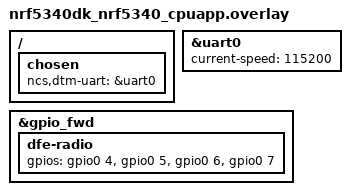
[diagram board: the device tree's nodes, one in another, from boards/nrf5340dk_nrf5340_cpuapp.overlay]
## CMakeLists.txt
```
#
# Copyright (c) 2023 Nordic Semiconductor ASA
#
# SPDX-License-Identifier: LicenseRef-Nordic-5-Clause
#

cmake_minimum_required(VERSION 3.20.0)

find_package(Zephyr REQUIRED HINTS $ENV{ZEPHYR_BASE})
project(remote_hci)

target_include_directories(app PRIVATE ./../rpc)
target_include_directories(app PRIVATE ./../src/transport)

# NORDIC SDK APP START
target_sources(app PRIVATE
  src/main.c
  ../src/transport/hci_uart.c
)
# NORDIC SDK APP END
```

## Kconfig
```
#
# Copyright (c) 2023 Nordic Semiconductor
#
# SPDX-License-Identifier: LicenseRef-Nordic-5-Clause
#

mainmenu "Nordic Remote HCI DTM"

config DTM_REMOTE_HCI_CHILD
	bool
	default y

config DTM_PUT_THREAD_STACK_SIZE
	int "dtm_put thread stack size"
	default 2048
	help
	  Stack size of the dtm_put thread.

config DTM_PUT_THREAD_PRIORITY
	int "dtm_put thread priority"
	default 7
	help
	  Priority of the dtm_put thread.

config REMOTE_HCI_QUEUE_COUNT
	int "Count of HCI RX/TX queues"
	default 16
	help
	  Maximum depth of the HCI RX/TX queues.

config REMOTE_HCI_QUEUE_SIZE
	int "Size of HCI RX/TX queue buffer"
	default 1024
	help
	  Maximum size of the HCI RX/TX queue element.

config REMOTE_HCI_TX_THREAD_STACK_SIZE
	int "Stack size of TX thread"
	default 2048
	help
	  Stack size of the TX thread.

config REMOTE_HCI_TX_THREAD_PRIORITY
	int "TX thread priority"
	default 7
	help
	  Priority of the TX thread.

module = DTM_REMOTE_HCI
module-str = "DTM_remote_hci"
source "${ZEPHYR_BASE}/subsys/logging/Kconfig.template.log_config"

source "Kconfig.zephyr"
```

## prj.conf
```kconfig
#
# Copyright (c) 2023 Nordic Semiconductor ASA
#
# SPDX-License-Identifier: LicenseRef-Nordic-5-Clause
#
CONFIG_ASSERT=y
CONFIG_ASSERT_NO_COND_INFO=y
CONFIG_ASSERT_NO_MSG_INFO=y

CONFIG_HW_STACK_PROTECTION=y

CONFIG_CONSOLE=n
CONFIG_UART_CONSOLE=n
CONFIG_LOG=y
CONFIG_LOG_PRINTK=y
CONFIG_USE_SEGGER_RTT=y
CONFIG_LOG_BACKEND_RTT=y
CONFIG_UART_ASYNC_API=y

CONFIG_NRF_RPC=y
CONFIG_NRF_RPC_CBOR=y
CONFIG_IDLE_STACK_SIZE=2048

CONFIG_NET_BUF=y

CONFIG_SOC_NRF53_CPUNET_ENABLE=y
```

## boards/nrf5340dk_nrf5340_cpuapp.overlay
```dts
/*
 * Copyright (c) 2023 Nordic Semiconductor ASA
 *
 * SPDX-License-Identifier: LicenseRef-Nordic-5-Clause
 */

/ {
	chosen {
		ncs,dtm-uart = &uart0;
	};
};

&uart0 {
	status = "okay";
	current-speed = <115200>;
};

&gpio_fwd {
	dfe-radio {
	    gpios = <&gpio0 4 0>,
		<&gpio0 5 0>,
		<&gpio0 6 0>,
		<&gpio0 7 0>;
	};
};
```

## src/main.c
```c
/*
 * Copyright (c) 2023 Nordic Semiconductor ASA
 *
 * SPDX-License-Identifier: LicenseRef-Nordic-5-Clause
 */

#include <zephyr/kernel.h>
#include <zephyr/init.h>
#include <zephyr/net_buf.h>
#include <zephyr/logging/log.h>
#include <nrf_rpc/nrf_rpc_ipc.h>
#include <nrf_rpc_cbor.h>

#include "hci_uart.h"
#include "dtm_serialization.h"

LOG_MODULE_REGISTER(serialization_layer, CONFIG_DTM_REMOTE_HCI_LOG_LEVEL);

NRF_RPC_IPC_TRANSPORT(hci_group_tr, DEVICE_DT_GET(DT_NODELABEL(ipc0)), "dtm_ept");
NRF_RPC_GROUP_DEFINE(hci_group, "hci_remote", &hci_group_tr, NULL, NULL, NULL);

static K_FIFO_DEFINE(dtm_put_queue);

static void dtm_hci_put_wrapper(struct net_buf *buf);

static void rsp_error_code_send(const struct nrf_rpc_group *group, int err_code)
{
	struct nrf_rpc_cbor_ctx ctx;
	size_t buffer_size_max = 5;

	NRF_RPC_CBOR_ALLOC(group, ctx, buffer_size_max);

	if (!zcbor_int32_put(ctx.zs, err_code)) {
		goto error_exit;
	}

	nrf_rpc_cbor_rsp_no_err(group, &ctx);

	return;

error_exit:
	__ASSERT_NO_MSG(false);
}

/* Outgoing event dtm_hci_put to network core (DTM). */
static void dtm_hci_put_remote(struct net_buf *buf)
{
	struct nrf_rpc_cbor_ctx ctx;
	size_t buffer_size_max = 10;

	LOG_DBG("Call to dtm_hci_put");

	buffer_size_max += buf->len;

	NRF_RPC_CBOR_ALLOC(&hci_group, ctx, buffer_size_max);

	if (!zcbor_uint_encode(ctx.zs, &buf->user_data[0], sizeof(buf->user_data[0]))) {
		goto error_exit;
	}

	if (!zcbor_bstr_encode_ptr(ctx.zs, buf->data, buf->len)) {
		goto error_exit;
	}

	nrf_rpc_cbor_evt(&hci_group, RPC_DTM_HCI_PUT_EVT, &ctx);

	return;

error_exit:
	__ASSERT_NO_MSG(false);
}

/* Incoming hci_uart_write command from network core (DTM) */
static void hci_uart_write_handler(const struct nrf_rpc_group *group, struct nrf_rpc_cbor_ctx *ctx,
				  void *handler_data)
{
	int err;
	uint8_t type;
	struct zcbor_string hdr;
	struct zcbor_string pld;

	LOG_DBG("Call from hci_uart_write");

	if (!zcbor_uint_decode(ctx->zs, &type, sizeof(type))) {
		goto error_exit;
	}

	if (!zcbor_bstr_decode(ctx->zs, &hdr)) {
		goto error_exit;
	}

	if (!zcbor_bstr_decode(ctx->zs, &pld)) {
		goto error_exit;
	}

	err = hci_uart_write(type, hdr.value, hdr.len, pld.value, pld.len);
	nrf_rpc_cbor_decoding_done(group, ctx);
	rsp_error_code_send(group, err);

	return;

error_exit:
	__ASSERT_NO_MSG(false);
}

NRF_RPC_CBOR_CMD_DECODER(hci_group, hci_uart_write, RPC_HCI_UART_WRITE_CMD,
			 hci_uart_write_handler, NULL);

/* Incoming command hci_uart_init from network core (DTM). */
static void hci_uart_init_handler(const struct nrf_rpc_group *group, struct nrf_rpc_cbor_ctx *ctx,
				  void *handler_data)
{
	int err;

	LOG_DBG("Call from hci_uart_init");
	nrf_rpc_cbor_decoding_done(group, ctx);

	err = hci_uart_init(dtm_hci_put_wrapper);
	rsp_error_code_send(group, err);
}

NRF_RPC_CBOR_CMD_DECODER(hci_group, hci_uart_init, RPC_HCI_UART_INIT_CMD,
			 hci_uart_init_handler, NULL);

static void dtm_hci_put_wrapper(struct net_buf *buf)
{
	k_fifo_put(&dtm_put_queue, buf);
}

static void dtm_put_thread(void)
{
	struct net_buf *buf;

	for (;;) {
		buf = k_fifo_get(&dtm_put_queue, K_FOREVER);

		__ASSERT_NO_MSG(buf != NULL);

		dtm_hci_put_remote(buf);
		net_buf_unref(buf);
	}
}

K_THREAD_DEFINE(dtm_put_thread_id, CONFIG_DTM_PUT_THREAD_STACK_SIZE, dtm_put_thread,
		NULL, NULL, NULL,
		CONFIG_DTM_PUT_THREAD_PRIORITY, 0, 0);

static void err_handler(const struct nrf_rpc_err_report *report)
{
	LOG_ERR("nRF RPC error %d ocurred. See nRF RPC logs for more details.", report->code);
	k_oops();
}

int main(void)
{
	int err;

	LOG_INF("RPC init begin");

	err = nrf_rpc_init(err_handler);
	if (err) {
		LOG_ERR("nrf_rpc_init failed: %d", err);
		return -EIO;
	}

	LOG_INF("RPC init done");

	return 0;
}
```
